# STM32WBA64 register map
File version: 1.1
CPU: CM33 r0p1, little endian, MPU, FPU, 4 interrupt priority bits
Registers are 32-bit, read-write, reset 0x0 unless marked. A register's access mark holds for its fields unless they carry their own. Offsets are from the block's base; [hi:lo] are bit positions; {n}, {i} and the like mark numbered series; 'fields as' and 'values as' point back to an identical list.

## PWR — PWR address block description
Base 0x46020800
Same registers: SEC_PWR 0x56020800
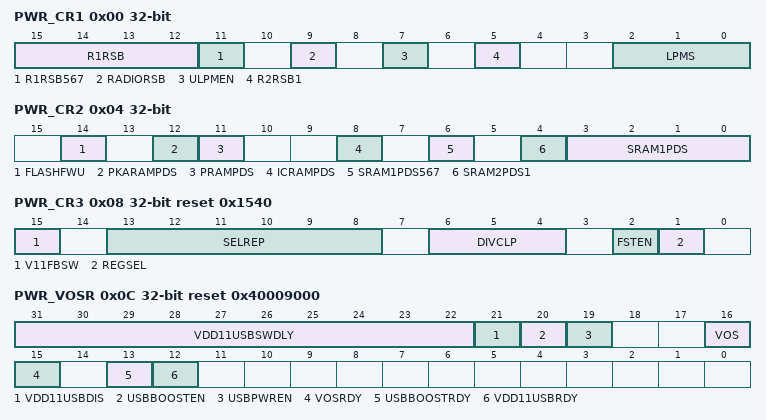
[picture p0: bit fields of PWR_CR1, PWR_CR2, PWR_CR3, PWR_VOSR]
0x00 PWR_CR1 — PWR control register 1
  [15:12] R1RSB — SRAM1 64 KB page x retention in Standby mode
    0=SRAM1 64 KB, page x content not retained in Standby mode; 1=SRAM1 64 KB, page x content retained in Standby mode
  [11] R1RSB567 — SRAM1 192 KB page 5 to 7 retention in Standby mode
    0=SRAM1 192 KB, page 5 to 7 content not retained in Standby mode; 1=SRAM1 192 KB, page 5 to 7 content retained in Standby mode
  [9] RADIORSB — 2.
    0=2; 1=2
  [7] ULPMEN — BOR0 ultra-low power mode.
    0=BOR0 operating in continuous (normal) mode in all operating modes; 1=BOR0 operating in discontinuous (ultra-low power) mode in Stop 1 and Standby modes
  [5] R2RSB1 — SRAM2 retention in Standby mode
    0=SRAM2 content not retained in Standby mode; 1=SRAM2 content retained in Standby mode
  [2:0] LPMS — Low-power mode selection
    0=Stop 0 mode; 1=Stop 1 mode
0x04 PWR_CR2 — PWR control register 2
  [14] FLASHFWU — Flash memory fast wake-up from Stop modes (Stop 0, 1)
    0=Flash memory enters low-power mode in Stop 0 and Stop 1 modes (lower power consumption); 1=Flash memory remains in normal mode in Stop 0 and Stop 1 modes (faster wake-up time)
  [12] PKARAMPDS — PKA SRAM power-down in Stop modes
    0=PKA SRAM content retained in Stop modes; 1=PKA SRAM content lost in Stop modes
  [11] PRAMPDS — OTG SRAM power-down in Stop modes
    0=OTG SRAM content retained in Stop modes; 1=OTG SRAM content lost in Stop modes
  [8] ICRAMPDS — ICACHE SRAM power-down in Stop modes (Stop 0, 1)
    0=ICACHE SRAM content retained in Stop modes; 1=ICACHE SRAM content lost in Stop modes
  [6] SRAM1PDS567 — SRAM1 192 KB, page 5 to 7 power-down in Stop modes
    0=SRAM1 192 KB, page 5 to 7 content retained in Stop modes; 1=SRAM1 192 KB, page 5 to 7 content lost in Stop modes
  [4] SRAM2PDS1 — SRAM2 power-down in Stop modes (Stop 0, 1)
    0=SRAM2 content retained in Stop modes; 1=SRAM2 content lost in Stop modes
  [3:0] SRAM1PDS — SRAM1 page x power-down in Stop modes
    0=SRAM1 64 KB page x content retained in Stop modes; 1=SRAM1 64 KB page x content lost in Stop modes
0x08 PWR_CR3 reset 0x1540 — PWR control register 3
  [15] V11FBSW — V11 feedback switch enable (non user bit)
    0=V11 feedback fixed before Epod; 1=V11 feedback switch enabled:
  [13:8] SELREP — Low power mode regulator replica selection
  [6:4] DIVCLP — Low power mode regulator clock division
    0=Low power regulator clock not divided
  [2] FSTEN — Fast soft start
    0=LDO/SMPS fast startup disabled (limited inrush current after system reset and wake-up from Standby); 1=LDO/SMPS fast startup enabled
  [1] REGSEL — Regulator selection
    0=LDO selected; 1=SMPS selected
0x0C PWR_VOSR reset 0x40009000 — PWR voltage scaling register
  [31:22] VDD11USBSWDLY — USB OTG VDD11USB switch delay
  [21] VDD11USBDIS — USB OTG VDD11USB disable
    0=VDD11USB enabled; 1=VDD11USB disabled
  [20] USBBOOSTEN — USB OTG booster enable
    0=USB OTG booster disabled; 1=USB OTG booster enabled
  [19] USBPWREN — USB OTG power enable
    0=USB OTG power disabled; 1=USB OTG power enabled
  [16] VOS — Voltage scaling range selection
    0=Range 2 (lowest power); 1=Range 1 (highest frequency)
  [15] VOSRDY ro — Ready bit for Vless thansub COREless than/sub voltage scaling output selection
    0=Not ready, voltage level less than VOS selected level; 1=Ready, voltage level greater than or equal VOS selected level
  [13] USBBOOSTRDY ro — USB OTG booster ready
    0=USB OTG power booster not ready; 1=USB OTG power booster ready
  [12] VDD11USBRDY ro — USB OTG VDD11USB ready
    0=USB OTG VDD11USB not ready; 1=USB OTG VDD11USB ready
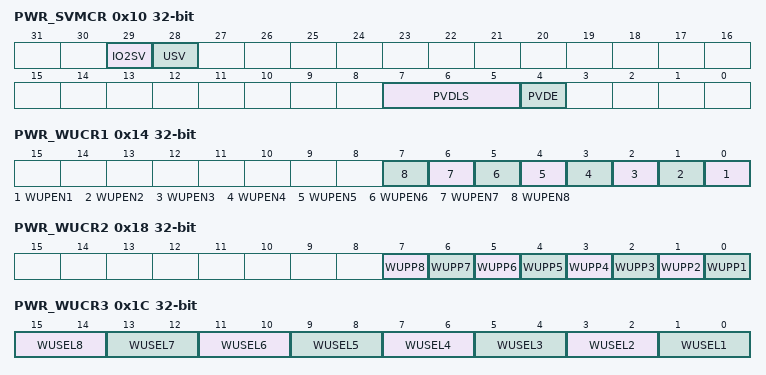
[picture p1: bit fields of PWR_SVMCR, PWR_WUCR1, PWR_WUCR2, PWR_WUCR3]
0x10 PWR_SVMCR — PWR supply voltage monitoring control register
  [29] IO2SV — VDDIO2 supply valid
    0=VDDIO2 not supplied, electrical and logical isolation enabled; 1=VDDIO2 supply present, electrical and logical isolation disabled
  [28] USV — VDDUSB supply valid
    0=VDDUSB not supplied, electrical and logical isolation enabled; 1=VDDUSB supply present, electrical and logical isolation disabled
  [7:5] PVDLS — Programmable voltage detector level selection
    {v}=Vless thansub PVD{v}less than/sub ~ 2 (v=0..6); 7=External input analog voltage PVD_IN (compared internally to VREFINT)
  [4] PVDE — Programmable voltage detector enable
    0=Programmable voltage detector disabled; 1=Programmable voltage detector enabled
0x14 PWR_WUCR1 — PWR wake-up control register 1
  [n-1] WUPEN{n} (n=1..8) — Wake-up and interrupt pin WKUP{n} enable
    0=Wake-up and interrupt pin WKUP{n} disabled; 1=Wake-up and interrupt pin WKUP{n} enabled
0x18 PWR_WUCR2 — PWR wake-up control register 2
  [all] fields
    0=Detection on high level (rising edge); 1=Detection on low level (falling edge)
  [n-1] WUPP{n} (n=2..8) — Wake-up pin WKUP{n} polarity
  [0] WUPP1 — Wake-up pin WKUP1 polarity.
0x1C PWR_WUCR3 — PWR wake-up control register 3
  [15:14] WUSEL8 — Wake-up and interrupt pin WKUP8 selection
    1=WKUP8_1; 2=WKUP8_2; 3=WKUP8_3 (internal source, does not generate a WKUP interrupt)
  [13:12] WUSEL7 — Wake-up and interrupt pin WKUP7 selection
    0=WKUP7_0; 1=WKUP7_1; 3=WKUP7_3 (internal source, does not generate a WKUP interrupt)
  [11:10] WUSEL6 — Wake-up and interrupt pin WKUP6 selection
    0=WKUP6_0; 1=WKUP6_1; 3=WKUP6_3 (internal source, does not generate a WKUP interrupt)
  [9:8] WUSEL5 — Wake-up and interrupt pin WKUP5 selection
    1=WKUP5_1; 2=WKUP5_2
  [7:6] WUSEL4 — Wake-up and interrupt pin WKUP4 selection
    0=WKUP4_0; 1=WKUP4_1
  [5:4] WUSEL3 — Wake-up and interrupt pin WKUP3 selection
    1=WKUP3_1; 2=WKUP3_2
  [3:2] WUSEL2 — Wake-up and interrupt pin WKUP2 selection
    0=WKUP2_0; 1=WKUP2_1
  [1:0] WUSEL1 — Wake-up and interrupt pin WKUP1 selection
    0=WKUP1_0; 1=WKUP1_1
0x28 PWR_DBPR — PWR disable Backup domain register
  [0] DBP — Disable Backup domain write protection
    0=Write access to Backup domain disabled; 1=Write access to Backup domain enabled
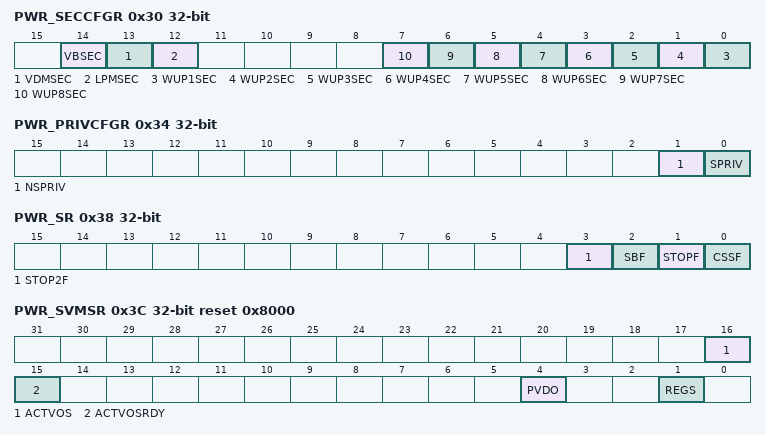
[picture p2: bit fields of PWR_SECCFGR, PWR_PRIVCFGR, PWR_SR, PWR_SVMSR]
0x30 PWR_SECCFGR — PWR security configuration register
  [14] VBSEC — Backup domain secure protection
    0=PWR_DBPR can be read and written with secure or non-secure access; 1=PWR_DBPR can be read and written only with secure access
  [13] VDMSEC — Voltage detection secure protection
    0=PWR_SVMCR and PWR_CR3 can be read and written with secure or non-secure access; 1=PWR_SVMCR and PWR_CR3 can be read and written only with secure access
  [12] LPMSEC — Low-power modes secure protection
    0=PWR_CR1, PWR_CR2 and CSSF in the PWR_SR can be read and written with secure or non-secure access; 1=PWR_CR1, PWR_CR2, and CSSF in the PWR_SR can be read and written only with secure access
  [n-1] WUP{n}SEC (n=1..8) — WUP{n} secure protection
    0=Bits related to the WKUP{n} pin in PWR_WUCR1, PWR_WUCR2, PWR_WUCR3 and PWR_WUSCR can be read and written with secure or non-secure access; 1=Bits related to the WKUP{n} pin in PWR_WUCR1, PWR_WUCR2, PWR_WUCR3 and PWR_WUSCR can be read and written only with secure access
0x34 PWR_PRIVCFGR — PWR privilege control register
  [1] NSPRIV — PWR non-secure functions privilege configuration
    0=Read and write to PWR non-secure functions can be done by privileged or unprivileged access; 1=Read and write to PWR non-secure functions can be done by privileged access only
  [0] SPRIV — PWR secure functions privilege configuration
    0=Read and write to PWR secure functions can be done by privileged or unprivileged access; 1=Read and write to PWR secure functions can be done by privileged access only
0x38 PWR_SR — PWR status register
  [3] STOP2F ro — Stop 2 mode peripherals power down flag
    0=The device did not enter Stop 2 mode; 1=The device entered Stop 2 mode
  [2] SBF ro — Standby flag
    0=The device did not enter Standby mode; 1=The device entered Standby mode
  [1] STOPF ro — Stop flag
    0=The device did not enter any Stop mode; 1=The device entered a Stop mode
  [0] CSSF wo — Clear Stop and Standby flags
0x3C PWR_SVMSR ro reset 0x8000 — PWR supply voltage monitoring status register
  [16] ACTVOS — VOS currently applied to Vless thansub COREless than/sub
    0=Range 2 (lowest power); 1=Range 1 (highest frequency)
  [15] ACTVOSRDY — Voltage level ready for currently used VOS
    0=Vless thansub COREless than/sub is above or below the current voltage scaling provided by ACTVOS; 1=Vless thansub CORE less than/sub is equal to the current voltage scaling provided by ACTVOS
  [4] PVDO — Programmable voltage detector output
    0=Vless thansub DDless than/sub is equal or above the PVD threshold selected by PVDLS[2:0]; 1=Vless thansub DD less than/sub is below the PVD threshold selected by PVDLS[2:0]
  [1] REGS — Regulator selection
    0=LDO selected; 1=SMPS selected
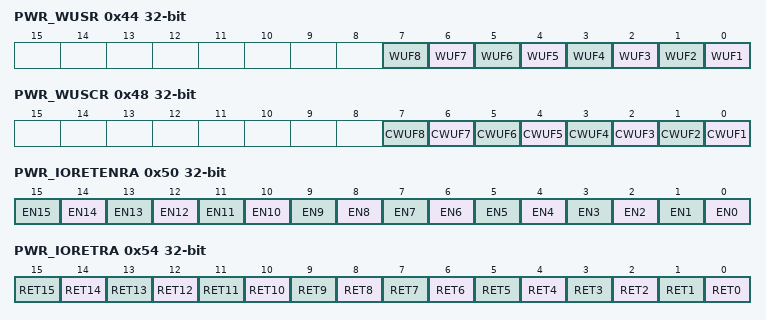
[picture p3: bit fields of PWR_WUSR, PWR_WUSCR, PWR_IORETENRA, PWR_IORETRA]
0x44 PWR_WUSR ro — PWR wake-up status register
  [n-1] WUF{n} (n=1..8) — Wake-up and interrupt pending flag {n}
0x48 PWR_WUSCR wo — PWR wake-up status clear register
  [n-1] CWUF{n} (n=1..8) — Clear wake-up flag {n}
0x50 PWR_IORETENRA — PWR port A Standby IO retention enable register
  [all] fields
    0=PAy Standby GPIO retention feature disabled; 1=PAy Standby GPIO retention feature enabled
  [n] EN{n} (n=0..15) — Port A Standby GPIO retention enable
0x54 PWR_IORETRA — PWR port A Standby IO retention status register
  [all] fields
    1=Set by hardware when Standby GPIO PAy is enabled in PWR_IORETENRA and Standby mode is entered; 0=Cleared by software, writing 0
  [n] RET{n} (n=0..15) — Port A Standby GPIO retention active
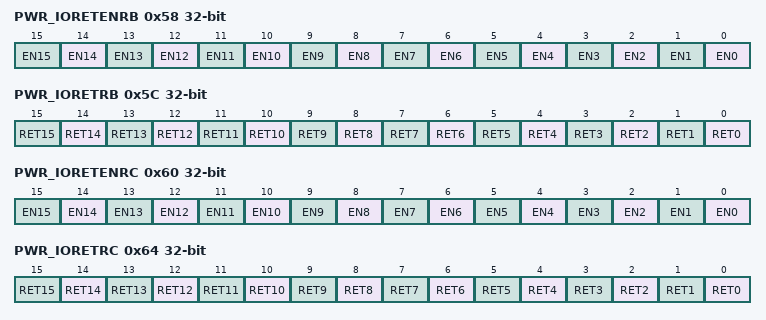
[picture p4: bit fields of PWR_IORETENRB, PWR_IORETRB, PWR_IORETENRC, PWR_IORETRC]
0x58 PWR_IORETENRB — PWR port B Standby IO retention enable register
  [all] fields
    0=PBy Standby GPIO retention feature disabled; 1=PBy Standby GPIO retention feature enabled
  [n] EN{n} (n=0..15) — Port B Standby GPIO retention enable
0x5C PWR_IORETRB — PWR port B Standby IO retention status register
  [all] fields
    1=Set by hardware when Standby GPIO PBy is enabled in PWR_IORETENRB and Standby mode is entered; 0=Cleared by software, writing 0
  [n] RET{n} (n=0..15) — Port B Standby GPIO retention active
0x60 PWR_IORETENRC — PWR port C Standby IO retention enable register
  [all] fields
    0=PCy Standby GPIO retention feature disabled; 1=PCy Standby GPIO retention feature enabled
  [n] EN{n} (n=0..15) — Port C Standby GPIO retention enable
0x64 PWR_IORETRC — PWR port C Standby IO retention status register
  [all] fields
    1=Set by hardware when Standby GPIO PCy is enabled in PWR_IORETENRC and Standby mode is entered; 0=Cleared by software, writing 0
  [n] RET{n} (n=0..15) — Port C Standby GPIO retention active
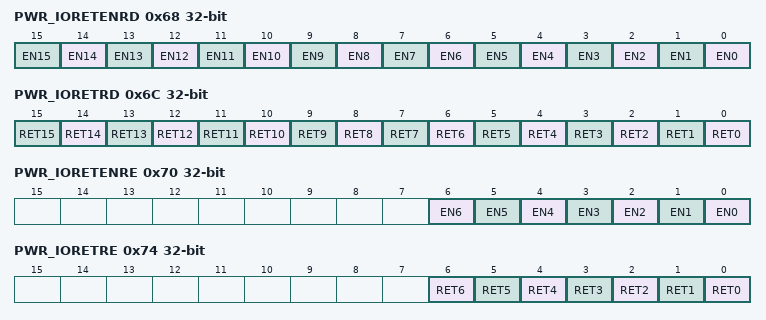
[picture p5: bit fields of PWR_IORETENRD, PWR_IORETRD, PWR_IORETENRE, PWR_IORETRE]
0x68 PWR_IORETENRD — PWR port D Standby IO retention enable register
  [all] fields
    0=PDy Standby GPIO retention feature disabled; 1=PDy Standby GPIO retention feature enabled
  [n] EN{n} (n=0..15) — Port D Standby GPIO retention enable
0x6C PWR_IORETRD — PWR port D Standby IO retention status register
  [all] fields
    1=Set by hardware when Standby GPIO PDy is enabled in PWR_IORETENRD and Standby mode is entered; 0=Cleared by software, writing 0
  [n] RET{n} (n=0..15) — Port D Standby GPIO retention active
0x70 PWR_IORETENRE — PWR port E Standby IO retention enable register
  [all] fields
    0=PEy Standby GPIO retention feature disabled; 1=PEy Standby GPIO retention feature enabled
  [n] EN{n} (n=0..6) — Port E Standby GPIO retention enable
0x74 PWR_IORETRE — PWR port E Standby IO retention status register
  [all] fields
    1=Set by hardware when Standby GPIO PEy is enabled in PWR_IORETENRE and Standby mode is entered; 0=Cleared by software, writing 0
  [n] RET{n} (n=0..6) — Port E Standby GPIO retention active
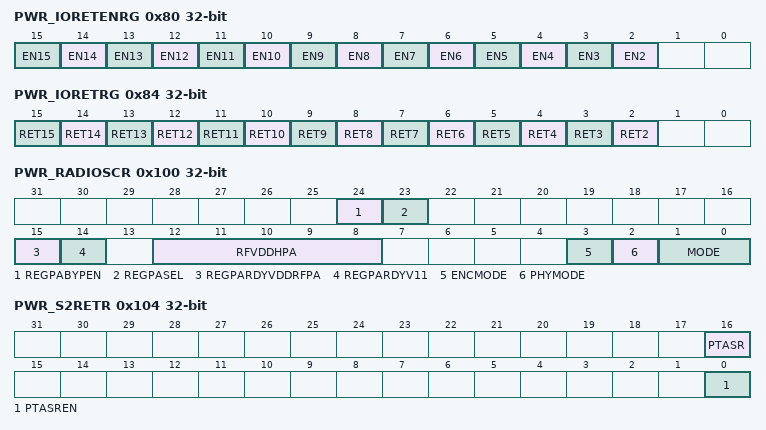
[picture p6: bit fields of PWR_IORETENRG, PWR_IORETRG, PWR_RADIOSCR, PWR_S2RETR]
0x80 PWR_IORETENRG — PWR port G Standby IO retention enable register
  [all] fields
    0=PGy Standby GPIO retention feature disabled; 1=PGy Standby GPIO retention feature enabled
  [n] EN{n} (n=2..15) — Port G Standby GPIO retention enable
0x84 PWR_IORETRG — PWR port G Standby IO retention status register
  [all] fields
    1=Set by hardware when Standby GPIO PGy is enabled in PWR_IORETENRG and Standby mode is entered; 0=Cleared by software, writing 0
  [n] RET{n} (n=2..15) — Port G Standby GPIO retention active
0x88 PWR_IORETENRH — PWR port H Standby IO retention enable register
  [3] EN3 — Port H Standby GPIO retention enable
    0=PHy Standby GPIO retention feature disabled; 1=PHy Standby GPIO retention feature enabled
0x8C PWR_IORETRH — PWR port H Standby IO retention status register
  [3] RET3 — Port H Standby GPIO retention active
    1=Set by hardware when Standby GPIO PHy is enabled in PWR_IORETENRH and Standby mode is entered; 0=Cleared by software, writing 0
0x100 PWR_RADIOSCR — PWR 2.
  [24] REGPABYPEN — regulator REG_VDDHPA bypass enable.
    0=2; 1=2
  [23] REGPASEL — regulator REG_VDDHPA input supply selection.
    0=VDDRFPA pin selected as regulator REG_VDDHPA input supply; 1=regulator REG_VDDHPA input supply selection between VDDRFPA and VDD11, dependent on requested regulated output voltage
  [15] REGPARDYVDDRFPA ro — Ready bit for Vless thansub DDHPAless than/sub voltage level when selecting VDDRFPA input.
    0=Not ready, Vless thansub DDHPAless than/sub voltage level less than REGPAVOS selected supply level; 1=Ready, Vless thansub DDHPAless than/sub voltage level greater than or equal REGPAVOS selected supply level
  [14] REGPARDYV11 ro — Ready bit for Vless thansub DDHPAless than/sub voltage level when selecting VDD11 input.
    values as REGPARDYVDDRFPA
  [12:8] RFVDDHPA ro — 2.
  [3] ENCMODE ro — 2.
    0=2; 1=2
  [2] PHYMODE ro — 2.
    0=2; 1=2
  [1:0] MODE ro — 2.
    0=2; 1=2
0x104 PWR_S2RETR — PWR Stop 2 peripheral IOs retention register
  [16] PTASR — PTA interface output signals state retention in Stop 2 mode active.
    1=Set by hardware when Stop 2 mode PTA retention is enabled in PTASREN and Stop 2 mode is entered; 0=Cleared by software, writing 0
  [0] PTASREN — PTA output signals Stop 2 mode retention enable
    0=PTA output signals Stop 2 retention feature disabled; 1=PTA output signals Stop 2 retention feature enabled
